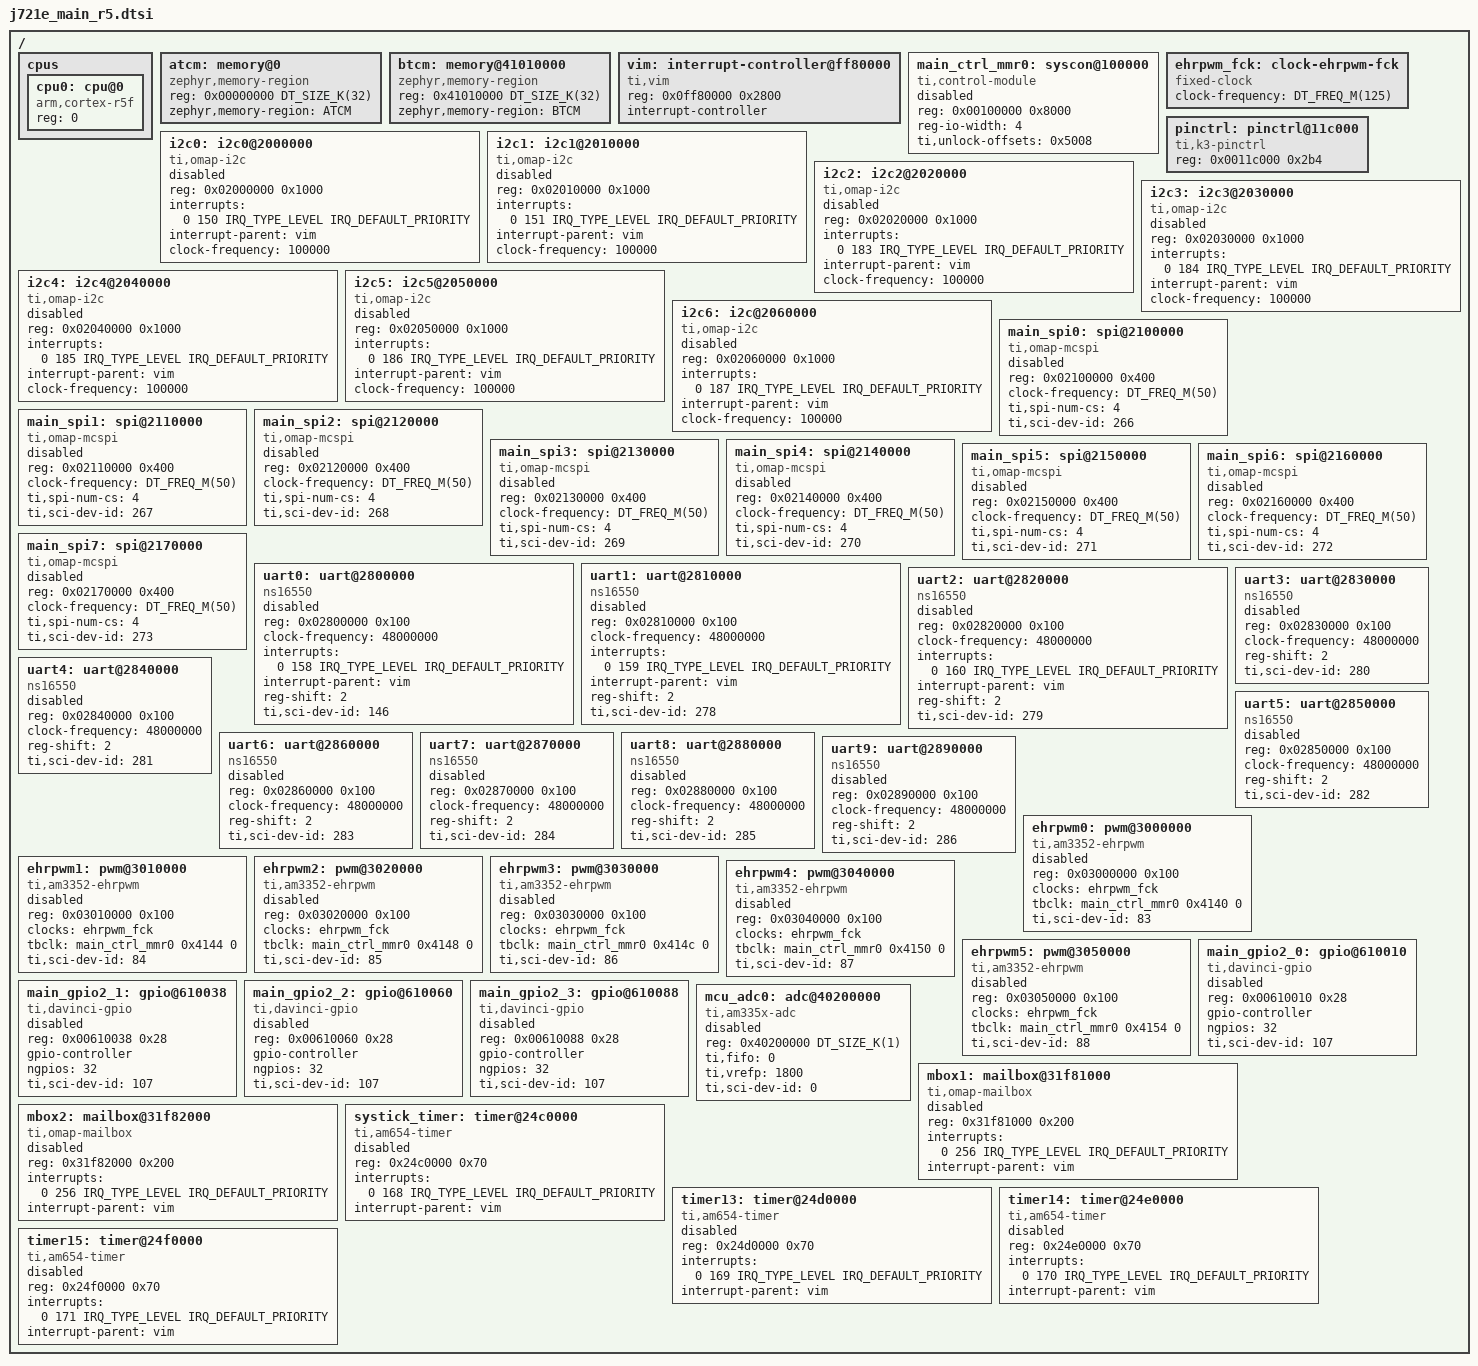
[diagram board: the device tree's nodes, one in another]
/* Copyright (C) 2023 BeagleBoard.org Foundation
 * Copyright (C) 2023 S Prashanth
 * Copyright (c) 2024 Texas Instruments Incorporated
 *	Andrew Davis <afd@ti.com>
 *
 * SPDX-License-Identifier: Apache-2.0
 */

#include <mem.h>
#include <freq.h>
#include <arm/armv7-r.dtsi>
#include <zephyr/dt-bindings/interrupt-controller/ti-vim.h>
#include <ti/j721e_main.dtsi>

/ {
	#address-cells = <1>;
	#size-cells = <1>;

	cpus {
		#address-cells = <1>;
		#size-cells = <0>;

		cpu0: cpu@0 {
			device_type = "cpu";
			compatible = "arm,cortex-r5f";
			reg = <0>;
		};
	};

	atcm: memory@0 {
		device_type = "memory";
		compatible = "zephyr,memory-region", "mmio-sram";
		reg = <0x00000000 DT_SIZE_K(32)>;
		zephyr,memory-region = "ATCM";
	};

	btcm: memory@41010000 {
		device_type = "memory";
		compatible = "zephyr,memory-region", "mmio-sram";
		reg = <0x41010000 DT_SIZE_K(32)>;
		zephyr,memory-region = "BTCM";
	};

	vim: interrupt-controller@ff80000 {
		#address-cells = <1>;
		compatible = "ti,vim";
		reg = <0x0ff80000 0x2800>;
		interrupt-controller;
		#interrupt-cells = <4>; /* {IRQ/FIQ, IRQ_NUM, IRQ_TYPE, IRQ_PRIO} */
		status = "okay";
	};

	/* MAIN CTRL_MMR0, partition 1: the eHRPWM time-base clock enables (EPWMn_CTRL) */
	main_ctrl_mmr0: syscon@100000 {
		compatible = "ti,control-module", "syscon";
		reg = <0x00100000 0x8000>;
		reg-io-width = <4>;
		ti,unlock-offsets = <0x5008>;
		#epwm-tbclk-cells = <2>;
		status = "disabled";
	};

	/* eHRPWM functional clock: MAIN_SYSCLK0 / 4 */
	ehrpwm_fck: clock-ehrpwm-fck {
		compatible = "fixed-clock";
		clock-frequency = <DT_FREQ_M(125)>;
		#clock-cells = <0>;
	};

	pinctrl: pinctrl@11c000 {
		compatible = "ti,k3-pinctrl";
		reg = <0x0011c000 0x2b4>;
		status = "okay";
	};

	i2c0: i2c0@2000000 {
		compatible = "ti,omap-i2c";
		reg = <0x02000000 0x1000>;
		interrupts = <0 150 IRQ_TYPE_LEVEL IRQ_DEFAULT_PRIORITY>;
		interrupt-parent = <&vim>;
		clock-frequency = <100000>;
		#address-cells = <1>;
		#size-cells = <0>;
		status = "disabled";
	};

	i2c1: i2c1@2010000 {
		compatible = "ti,omap-i2c";
		reg = <0x02010000 0x1000>;
		interrupts = <0 151 IRQ_TYPE_LEVEL IRQ_DEFAULT_PRIORITY>;
		interrupt-parent = <&vim>;
		clock-frequency = <100000>;
		#address-cells = <1>;
		#size-cells = <0>;
		status = "disabled";
	};

	i2c2: i2c2@2020000 {
		compatible = "ti,omap-i2c";
		reg = <0x02020000 0x1000>;
		interrupts = <0 183 IRQ_TYPE_LEVEL IRQ_DEFAULT_PRIORITY>;
		interrupt-parent = <&vim>;
		clock-frequency = <100000>;
		#address-cells = <1>;
		#size-cells = <0>;
		status = "disabled";
	};

	i2c3: i2c3@2030000 {
		compatible = "ti,omap-i2c";
		reg = <0x02030000 0x1000>;
		interrupts = <0 184 IRQ_TYPE_LEVEL IRQ_DEFAULT_PRIORITY>;
		interrupt-parent = <&vim>;
		clock-frequency = <100000>;
		#address-cells = <1>;
		#size-cells = <0>;
		status = "disabled";
	};

	i2c4: i2c4@2040000 {
		compatible = "ti,omap-i2c";
		reg = <0x02040000 0x1000>;
		interrupts = <0 185 IRQ_TYPE_LEVEL IRQ_DEFAULT_PRIORITY>;
		interrupt-parent = <&vim>;
		clock-frequency = <100000>;
		#address-cells = <1>;
		#size-cells = <0>;
		status = "disabled";
	};

	i2c5: i2c5@2050000 {
		compatible = "ti,omap-i2c";
		reg = <0x02050000 0x1000>;
		interrupts = <0 186 IRQ_TYPE_LEVEL IRQ_DEFAULT_PRIORITY>;
		interrupt-parent = <&vim>;
		clock-frequency = <100000>;
		#address-cells = <1>;
		#size-cells = <0>;
		status = "disabled";
	};

	i2c6: i2c@2060000 {
		compatible = "ti,omap-i2c";
		reg = <0x02060000 0x1000>;
		interrupts = <0 187 IRQ_TYPE_LEVEL IRQ_DEFAULT_PRIORITY>;
		interrupt-parent = <&vim>;
		clock-frequency = <100000>;
		#address-cells = <1>;
		#size-cells = <0>;
		status = "disabled";
	};

	main_spi0: spi@2100000 {
		compatible = "ti,omap-mcspi";
		reg = <0x02100000 0x400>;
		clock-frequency = <DT_FREQ_M(50)>;
		ti,spi-num-cs = <4>;
		ti,sci-dev-id = <266>;
		#address-cells = <1>;
		#size-cells = <0>;
		status = "disabled";
	};

	main_spi1: spi@2110000 {
		compatible = "ti,omap-mcspi";
		reg = <0x02110000 0x400>;
		clock-frequency = <DT_FREQ_M(50)>;
		ti,spi-num-cs = <4>;
		ti,sci-dev-id = <267>;
		#address-cells = <1>;
		#size-cells = <0>;
		status = "disabled";
	};

	main_spi2: spi@2120000 {
		compatible = "ti,omap-mcspi";
		reg = <0x02120000 0x400>;
		clock-frequency = <DT_FREQ_M(50)>;
		ti,spi-num-cs = <4>;
		ti,sci-dev-id = <268>;
		#address-cells = <1>;
		#size-cells = <0>;
		status = "disabled";
	};

	main_spi3: spi@2130000 {
		compatible = "ti,omap-mcspi";
		reg = <0x02130000 0x400>;
		clock-frequency = <DT_FREQ_M(50)>;
		ti,spi-num-cs = <4>;
		ti,sci-dev-id = <269>;
		#address-cells = <1>;
		#size-cells = <0>;
		status = "disabled";
	};

	main_spi4: spi@2140000 {
		compatible = "ti,omap-mcspi";
		reg = <0x02140000 0x400>;
		clock-frequency = <DT_FREQ_M(50)>;
		ti,spi-num-cs = <4>;
		ti,sci-dev-id = <270>;
		#address-cells = <1>;
		#size-cells = <0>;
		status = "disabled";
	};

	main_spi5: spi@2150000 {
		compatible = "ti,omap-mcspi";
		reg = <0x02150000 0x400>;
		clock-frequency = <DT_FREQ_M(50)>;
		ti,spi-num-cs = <4>;
		ti,sci-dev-id = <271>;
		#address-cells = <1>;
		#size-cells = <0>;
		status = "disabled";
	};

	main_spi6: spi@2160000 {
		compatible = "ti,omap-mcspi";
		reg = <0x02160000 0x400>;
		clock-frequency = <DT_FREQ_M(50)>;
		ti,spi-num-cs = <4>;
		ti,sci-dev-id = <272>;
		#address-cells = <1>;
		#size-cells = <0>;
		status = "disabled";
	};

	main_spi7: spi@2170000 {
		compatible = "ti,omap-mcspi";
		reg = <0x02170000 0x400>;
		clock-frequency = <DT_FREQ_M(50)>;
		ti,spi-num-cs = <4>;
		ti,sci-dev-id = <273>;
		#address-cells = <1>;
		#size-cells = <0>;
		status = "disabled";
	};

	uart0: uart@2800000 {
		compatible = "ns16550";
		reg = <0x02800000 0x100>;
		clock-frequency = <48000000>;
		interrupts = <0 158 IRQ_TYPE_LEVEL IRQ_DEFAULT_PRIORITY>;
		interrupt-parent = <&vim>;
		reg-shift = <2>;
		ti,sci-dev-id = <146>;
		status = "disabled";
	};

	uart1: uart@2810000 {
		compatible = "ns16550";
		reg = <0x02810000 0x100>;
		clock-frequency = <48000000>;
		interrupts = <0 159 IRQ_TYPE_LEVEL IRQ_DEFAULT_PRIORITY>;
		interrupt-parent = <&vim>;
		reg-shift = <2>;
		ti,sci-dev-id = <278>;
		status = "disabled";
	};

	uart2: uart@2820000 {
		compatible = "ns16550";
		reg = <0x02820000 0x100>;
		clock-frequency = <48000000>;
		interrupts = <0 160 IRQ_TYPE_LEVEL IRQ_DEFAULT_PRIORITY>;
		interrupt-parent = <&vim>;
		reg-shift = <2>;
		ti,sci-dev-id = <279>;
		status = "disabled";
	};

	uart3: uart@2830000 {
		compatible = "ns16550";
		reg = <0x02830000 0x100>;
		clock-frequency = <48000000>;
		/* interrupt: through this cluster's R5FSS interrupt router, see the core dtsi */
		reg-shift = <2>;
		ti,sci-dev-id = <280>;
		status = "disabled";
	};

	uart4: uart@2840000 {
		compatible = "ns16550";
		reg = <0x02840000 0x100>;
		clock-frequency = <48000000>;
		/* interrupt: through this cluster's R5FSS interrupt router, see the core dtsi */
		reg-shift = <2>;
		ti,sci-dev-id = <281>;
		status = "disabled";
	};

	uart5: uart@2850000 {
		compatible = "ns16550";
		reg = <0x02850000 0x100>;
		clock-frequency = <48000000>;
		/* interrupt: through this cluster's R5FSS interrupt router, see the core dtsi */
		reg-shift = <2>;
		ti,sci-dev-id = <282>;
		status = "disabled";
	};

	uart6: uart@2860000 {
		compatible = "ns16550";
		reg = <0x02860000 0x100>;
		clock-frequency = <48000000>;
		/* interrupt: through this cluster's R5FSS interrupt router, see the core dtsi */
		reg-shift = <2>;
		ti,sci-dev-id = <283>;
		status = "disabled";
	};

	uart7: uart@2870000 {
		compatible = "ns16550";
		reg = <0x02870000 0x100>;
		clock-frequency = <48000000>;
		/* interrupt: through this cluster's R5FSS interrupt router, see the core dtsi */
		reg-shift = <2>;
		ti,sci-dev-id = <284>;
		status = "disabled";
	};

	uart8: uart@2880000 {
		compatible = "ns16550";
		reg = <0x02880000 0x100>;
		clock-frequency = <48000000>;
		/* interrupt: through this cluster's R5FSS interrupt router, see the core dtsi */
		reg-shift = <2>;
		ti,sci-dev-id = <285>;
		status = "disabled";
	};

	uart9: uart@2890000 {
		compatible = "ns16550";
		reg = <0x02890000 0x100>;
		clock-frequency = <48000000>;
		/* interrupt: through this cluster's R5FSS interrupt router, see the core dtsi */
		reg-shift = <2>;
		ti,sci-dev-id = <286>;
		status = "disabled";
	};

	ehrpwm0: pwm@3000000 {
		compatible = "ti,am3352-ehrpwm";
		reg = <0x03000000 0x100>;
		clocks = <&ehrpwm_fck>;
		tbclk = <&main_ctrl_mmr0 0x4140 0>;
		#pwm-cells = <3>;
		ti,sci-dev-id = <83>;
		status = "disabled";
	};

	ehrpwm1: pwm@3010000 {
		compatible = "ti,am3352-ehrpwm";
		reg = <0x03010000 0x100>;
		clocks = <&ehrpwm_fck>;
		tbclk = <&main_ctrl_mmr0 0x4144 0>;
		#pwm-cells = <3>;
		ti,sci-dev-id = <84>;
		status = "disabled";
	};

	ehrpwm2: pwm@3020000 {
		compatible = "ti,am3352-ehrpwm";
		reg = <0x03020000 0x100>;
		clocks = <&ehrpwm_fck>;
		tbclk = <&main_ctrl_mmr0 0x4148 0>;
		#pwm-cells = <3>;
		ti,sci-dev-id = <85>;
		status = "disabled";
	};

	ehrpwm3: pwm@3030000 {
		compatible = "ti,am3352-ehrpwm";
		reg = <0x03030000 0x100>;
		clocks = <&ehrpwm_fck>;
		tbclk = <&main_ctrl_mmr0 0x414c 0>;
		#pwm-cells = <3>;
		ti,sci-dev-id = <86>;
		status = "disabled";
	};

	ehrpwm4: pwm@3040000 {
		compatible = "ti,am3352-ehrpwm";
		reg = <0x03040000 0x100>;
		clocks = <&ehrpwm_fck>;
		tbclk = <&main_ctrl_mmr0 0x4150 0>;
		#pwm-cells = <3>;
		ti,sci-dev-id = <87>;
		status = "disabled";
	};

	ehrpwm5: pwm@3050000 {
		compatible = "ti,am3352-ehrpwm";
		reg = <0x03050000 0x100>;
		clocks = <&ehrpwm_fck>;
		tbclk = <&main_ctrl_mmr0 0x4154 0>;
		#pwm-cells = <3>;
		ti,sci-dev-id = <88>;
		status = "disabled";
	};

	/*
	 * MAIN GPIO2 drives the same pads as GPIO0 (GPIO2_n = GPIO0_n) from its
	 * own registers: the instance for a core that shares the pins with an
	 * OS owning GPIO0. One node per 32-pin bank.
	 */
	main_gpio2_0: gpio@610010 {
		compatible = "ti,davinci-gpio";
		reg = <0x00610010 0x28>;
		gpio-controller;
		#gpio-cells = <2>;
		ngpios = <32>;
		ti,sci-dev-id = <107>;
		status = "disabled";
	};

	main_gpio2_1: gpio@610038 {
		compatible = "ti,davinci-gpio";
		reg = <0x00610038 0x28>;
		gpio-controller;
		#gpio-cells = <2>;
		ngpios = <32>;
		ti,sci-dev-id = <107>;
		status = "disabled";
	};

	main_gpio2_2: gpio@610060 {
		compatible = "ti,davinci-gpio";
		reg = <0x00610060 0x28>;
		gpio-controller;
		#gpio-cells = <2>;
		ngpios = <32>;
		ti,sci-dev-id = <107>;
		status = "disabled";
	};

	main_gpio2_3: gpio@610088 {
		compatible = "ti,davinci-gpio";
		reg = <0x00610088 0x28>;
		gpio-controller;
		#gpio-cells = <2>;
		ngpios = <32>;
		ti,sci-dev-id = <107>;
		status = "disabled";
	};

	/*
	 * MCU_ADC0 (MCU domain, visible to the MAIN R5F cores): the analog
	 * inputs of the expansion headers. Its interrupt reaches a MAIN R5FSS
	 * through that cluster's interrupt router, see the core dtsi.
	 */
	mcu_adc0: adc@40200000 {
		compatible = "ti,am335x-adc";
		reg = <0x40200000 DT_SIZE_K(1)>;
		ti,fifo = <0>;
		ti,vrefp = <1800>;
		ti,sci-dev-id = <0>;
		#io-channel-cells = <1>;
		#address-cells = <1>;
		#size-cells = <0>;
		status = "disabled";
	};

	mbox1: mailbox@31f81000 {
		compatible = "ti,omap-mailbox";
		reg = <0x31f81000 0x200>;
		/* TODO: Use interrupt router to map this */
		/* R5FSS0_INTROUTER0_OUTL_0; TRM Table 9-47 */
		interrupts = <0 256 IRQ_TYPE_LEVEL IRQ_DEFAULT_PRIORITY>;
		interrupt-parent = <&vim>;
		#mbox-cells = <1>;
		status = "disabled";
	};

	mbox2: mailbox@31f82000 {
		compatible = "ti,omap-mailbox";
		reg = <0x31f82000 0x200>;
		/* TODO: Use interrupt router to map this */
		/* R5FSS1_INTROUTER0_OUTL_0; TRM Table 9-49 */
		interrupts = <0 256 IRQ_TYPE_LEVEL IRQ_DEFAULT_PRIORITY>;
		interrupt-parent = <&vim>;
		#mbox-cells = <1>;
		status = "disabled";
	};

	systick_timer: timer@24c0000 {
		compatible = "ti,am654-timer";
		reg = <0x24c0000 0x70>;
		/* TIMER12_INTR_PEND_0; TRM Table 9-47 */
		interrupts = <0 168 IRQ_TYPE_LEVEL IRQ_DEFAULT_PRIORITY>;
		interrupt-parent = <&vim>;
		status = "disabled";
	};

	timer13: timer@24d0000 {
		compatible = "ti,am654-timer";
		reg = <0x24d0000 0x70>;
		/* TIMER13_INTR_PEND_0; TRM Table 9-47 */
		interrupts = <0 169 IRQ_TYPE_LEVEL IRQ_DEFAULT_PRIORITY>;
		interrupt-parent = <&vim>;
		status = "disabled";
	};

	timer14: timer@24e0000 {
		compatible = "ti,am654-timer";
		reg = <0x24e0000 0x70>;
		/* TIMER14_INTR_PEND_0; TRM Table 9-47 */
		interrupts = <0 170 IRQ_TYPE_LEVEL IRQ_DEFAULT_PRIORITY>;
		interrupt-parent = <&vim>;
		status = "disabled";
	};

	timer15: timer@24f0000 {
		compatible = "ti,am654-timer";
		reg = <0x24f0000 0x70>;
		/* TIMER15_INTR_PEND_0; TRM Table 9-47 */
		interrupts = <0 171 IRQ_TYPE_LEVEL IRQ_DEFAULT_PRIORITY>;
		interrupt-parent = <&vim>;
		status = "disabled";
	};
};
